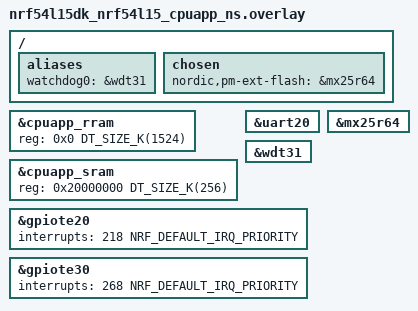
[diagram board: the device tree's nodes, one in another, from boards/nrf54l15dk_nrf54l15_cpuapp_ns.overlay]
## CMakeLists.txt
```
#
# Copyright (c) 2023 Nordic Semiconductor ASA
#
# SPDX-License-Identifier: LicenseRef-Nordic-5-Clause
#

cmake_minimum_required(VERSION 3.20.0)

find_package(Zephyr HINTS $ENV{ZEPHYR_BASE})

project(matter-template)

# Enable GNU STD support.
include(${ZEPHYR_CONNECTEDHOMEIP_MODULE_DIR}/config/nrfconnect/app/enable-gnu-std.cmake)

# NORDIC SDK APP START

# Include all source files that are located in the Matter common directory.
include(${ZEPHYR_NRF_MODULE_DIR}/samples/matter/common/cmake/source_common.cmake)

# Include Data Model utils
include(${ZEPHYR_NRF_MODULE_DIR}/samples/matter/common/cmake/data_model.cmake)

include(${ZEPHYR_NRF_MODULE_DIR}/samples/matter/common/cmake/zap_helpers.cmake)
ncs_get_zap_parent_dir(ZAP_PARENT_DIR)

target_include_directories(app PRIVATE
    src
    ${ZAP_PARENT_DIR}
)

target_sources(app PRIVATE
    src/app_task.cpp
    src/main.cpp
    src/temp_sensor_manager.cpp
    src/temperature_manager.cpp
    src/temperature_measurement/sensor.cpp
    src/zcl_callbacks.cpp
    ${ZEPHYR_NRF_MODULE_DIR}/samples/matter/common/src/binding/binding_handler.cpp
)

ncs_configure_data_model()
# NORDIC SDK APP END
```

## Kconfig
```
#
# Copyright (c) 2023 Nordic Semiconductor
#
# SPDX-License-Identifier: LicenseRef-Nordic-5-Clause
#
mainmenu "Matter Thermostat sample application"

config THERMOSTAT_TEMPERATURE_STEP
	int "Defines a simulated temperature step. Use 0 for random"
	default 0
	help
	  A temperature step that defines differences between consecutive simulated temperature measurements. If set to 0, then the step is random.

config THERMOSTAT_SIMULATED_TEMPERATURE_MAX
	int "Maximum simulated temperature value"
	default 3000

config THERMOSTAT_SIMULATED_TEMPERATURE_MIN
	int "Minimum simulated temperature value"
	default 1500

config THERMOSTAT_SIMULATED_TEMPERATURE_CHANGE
	bool "Select to set the temperature to rise or fall"
	default y
	help
	  If set to true, the simulated temperature is rising. If set to false, the simulated temperature is falling.

# Enable Read Client functionality for all build configurations.
config CHIP_ENABLE_READ_CLIENT
	default y

# Sample configuration used for Thread networking
if OPENTHREAD

choice OPENTHREAD_NORDIC_LIBRARY_CONFIGURATION
	default OPENTHREAD_NORDIC_LIBRARY_MTD
endchoice

choice OPENTHREAD_DEVICE_TYPE
	default OPENTHREAD_MTD
endchoice

endif # OPENTHREAD

source "${ZEPHYR_CONNECTEDHOMEIP_MODULE_DIR}/config/nrfconnect/chip-module/Kconfig.features"
source "${ZEPHYR_CONNECTEDHOMEIP_MODULE_DIR}/config/nrfconnect/chip-module/Kconfig.defaults"
source "${ZEPHYR_NRF_MODULE_DIR}/samples/matter/common/src/Kconfig"
source "Kconfig.zephyr"
```

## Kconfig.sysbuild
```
#
# Copyright (c) 2023 Nordic Semiconductor ASA
#
# SPDX-License-Identifier: LicenseRef-Nordic-5-Clause
#

config WIFI_NRF70
	default y if BOARD_NRF7002DK

#### Radio core selection
config NRF_DEFAULT_IPC_RADIO
	default y

# Enable IEEE802.15.4 serialization to network core
# This config automatically pulls in the `overlay-802154.conf` in the ipc_radio image
config NETCORE_IPC_RADIO_IEEE802154
	default y if SOC_SERIES_NRF53X && !WIFI_NRF70

# Enable Bluetooth serialization to network core
# This config automatically pulls in the `overlay-bt_hci_ipc.conf` in the ipc_radio image
config NETCORE_IPC_RADIO_BT_HCI_IPC
	default y if SOC_SERIES_NRF53X

#### Bootloader
choice BOOTLOADER
	default BOOTLOADER_MCUBOOT
endchoice

if BOOTLOADER_MCUBOOT

#### DFU multi-image support
config DFU_MULTI_IMAGE_PACKAGE_BUILD
	default y

config DFU_MULTI_IMAGE_PACKAGE_APP
	default y

config PM_EXTERNAL_FLASH_MCUBOOT_SECONDARY
	default y

#### DFU network core configuration
if SOC_SERIES_NRF53X

config MCUBOOT_UPDATEABLE_IMAGES
	default 2

choice MCUBOOT_MODE
	default MCUBOOT_MODE_OVERWRITE_ONLY
endchoice

choice BOOT_SIGNATURE_TYPE
	default BOOT_SIGNATURE_TYPE_RSA
endchoice

config SECURE_BOOT_NETCORE
	default y

config NETCORE_APP_UPDATE
	default y

config DFU_MULTI_IMAGE_PACKAGE_NET
	default y

endif # SOC_SERIES_NRF53X

if BOARD_NRF54L15DK

config PM_OVERRIDE_EXTERNAL_DRIVER_CHECK
	default y

endif # BOARD_NRF54L15DK

endif # BOOTLOADER_MCUBOOT

#### Enable generating factory data
config MATTER_FACTORY_DATA_GENERATE
	default y

source "share/sysbuild/Kconfig"
```

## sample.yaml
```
sample:
  description: Matter Thermostat sample
  name: Matter Thermostat
tests:
  sample.matter.thermostat.debug:
    sysbuild: true
    build_only: true
    integration_platforms:
      - nrf52840dk/nrf52840
      - nrf5340dk/nrf5340/cpuapp
      - nrf7002dk/nrf5340/cpuapp
      - nrf54l15dk/nrf54l15/cpuapp
      - nrf54l15dk/nrf54l15/cpuapp/ns
      - nrf54lm20pdk/nrf54lm20a/cpuapp
    platform_allow:
      - nrf52840dk/nrf52840
      - nrf5340dk/nrf5340/cpuapp
      - nrf7002dk/nrf5340/cpuapp
      - nrf54l15dk/nrf54l15/cpuapp
      - nrf54l15dk/nrf54l15/cpuapp/ns
      - nrf54lm20pdk/nrf54lm20a/cpuapp
    tags:
      - sysbuild
      - ci_samples_matter
  sample.matter.thermostat.release:
    sysbuild: true
    build_only: true
    extra_args:
      - FILE_SUFFIX=release
      - SB_CONFIG_BOOTLOADER_MCUBOOT=y
      - SB_CONFIG_PARTITION_MANAGER=y
    integration_platforms:
      - nrf52840dk/nrf52840
      - nrf5340dk/nrf5340/cpuapp
      - nrf7002dk/nrf5340/cpuapp
      - nrf54l15dk/nrf54l15/cpuapp
      - nrf54lm20pdk/nrf54lm20a/cpuapp
    platform_allow:
      - nrf52840dk/nrf52840
      - nrf5340dk/nrf5340/cpuapp
      - nrf7002dk/nrf5340/cpuapp
      - nrf54l15dk/nrf54l15/cpuapp
      - nrf54lm20pdk/nrf54lm20a/cpuapp
    tags:
      - sysbuild
      - ci_samples_matter
```

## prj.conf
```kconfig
#
# Copyright (c) 2023 Nordic Semiconductor ASA
#
# SPDX-License-Identifier: LicenseRef-Nordic-5-Clause
#

# This sample uses Kconfig.defaults to set options common for all
# samples. This file should contain only options specific for this sample
# or overrides of default values.

# Enable CHIP
CONFIG_CHIP=y
CONFIG_CHIP_PROJECT_CONFIG="src/chip_project_config.h"

# Configure ZAP file name
CONFIG_NCS_SAMPLE_MATTER_ZAP_FILE_PATH="${APPLICATION_CONFIG_DIR}/src/default_zap/thermostat.zap"

# 32782 == 0x800e (example thermostat product)
CONFIG_CHIP_DEVICE_PRODUCT_ID=32782
CONFIG_STD_CPP17=y

# Enable Matter pairing automatically on application start.
CONFIG_CHIP_ENABLE_PAIRING_AUTOSTART=y

# Enable Matter extended announcement and increase duration to 1 hour.
CONFIG_CHIP_BLE_EXT_ADVERTISING=y
CONFIG_CHIP_BLE_ADVERTISING_DURATION=60

# Add support for LEDs and buttons on Nordic development kits
CONFIG_DK_LIBRARY=y

# Bluetooth Low Energy configuration
CONFIG_BT_DEVICE_NAME="MatterThermo"

# Other settings
CONFIG_THREAD_NAME=y
CONFIG_MPU_STACK_GUARD=y
CONFIG_RESET_ON_FATAL_ERROR=n
CONFIG_CHIP_LIB_SHELL=y
CONFIG_NCS_SAMPLE_MATTER_TEST_SHELL=y

# Disable NFC onboarding
CONFIG_CHIP_NFC_ONBOARDING_PAYLOAD=y

# Reduce application size
CONFIG_USE_SEGGER_RTT=n

# Enable Factory Data feature
CONFIG_CHIP_FACTORY_DATA=y
CONFIG_CHIP_FACTORY_DATA_BUILD=y
```

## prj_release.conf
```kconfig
#
# Copyright (c) 2023 Nordic Semiconductor ASA
#
# SPDX-License-Identifier: LicenseRef-Nordic-5-Clause
#

# This sample uses Kconfig.defaults to set options common for all
# samples. This file should contain only options specific for this sample
# or overrides of default values.

# Enable CHIP
CONFIG_CHIP=y
CONFIG_CHIP_PROJECT_CONFIG="src/chip_project_config.h"

# Configure ZAP file name
CONFIG_NCS_SAMPLE_MATTER_ZAP_FILE_PATH="${APPLICATION_CONFIG_DIR}/src/default_zap/thermostat.zap"

# 32782 == 0x800e (example thermostat product)
CONFIG_CHIP_DEVICE_PRODUCT_ID=32782
CONFIG_STD_CPP17=y

# Enable Matter pairing automatically on application start.
CONFIG_CHIP_ENABLE_PAIRING_AUTOSTART=y

# Enable Matter extended announcement and increase duration to 1 hour.
CONFIG_CHIP_BLE_EXT_ADVERTISING=y
CONFIG_CHIP_BLE_ADVERTISING_DURATION=60

# Add support for LEDs and buttons on Nordic development kits
CONFIG_DK_LIBRARY=y

# Bluetooth Low Energy configuration
CONFIG_BT_DEVICE_NAME="MatterThermo"

# Enable system reset on fatal error
CONFIG_RESET_ON_FATAL_ERROR=y

# Disable all debug features
CONFIG_USE_SEGGER_RTT=n
CONFIG_SHELL=n
CONFIG_OPENTHREAD_SHELL=n
CONFIG_CONSOLE=n
CONFIG_UART_CONSOLE=n
CONFIG_SERIAL=n
CONFIG_LOG=n
CONFIG_LOG_MODE_MINIMAL=n
CONFIG_ASSERT_VERBOSE=n
CONFIG_ASSERT_NO_FILE_INFO=y
CONFIG_PRINTK=n
CONFIG_PRINTK_SYNC=n
CONFIG_THREAD_NAME=n

# Disable NFC onboarding
CONFIG_CHIP_NFC_ONBOARDING_PAYLOAD=n

# Enable Factory Data feature
CONFIG_CHIP_FACTORY_DATA=y
CONFIG_CHIP_FACTORY_DATA_BUILD=y

# Enable Watchdog
CONFIG_NCS_SAMPLE_MATTER_WATCHDOG=y

# Enable LTO to decrease the flash usage.
CONFIG_LTO=y
CONFIG_ISR_TABLES_LOCAL_DECLARATION=y
```

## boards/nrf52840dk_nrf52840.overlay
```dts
/* Copyright (c) 2023 Nordic Semiconductor ASA
 *
 * SPDX-License-Identifier: LicenseRef-Nordic-5-Clause
 */

 / {
	chosen {
		nordic,pm-ext-flash = &mx25r64;
	};
};

/* Disable unused peripherals to reduce power consumption */
&adc {
	status = "disabled";
};
&uart1 {
	status = "disabled";
};
&i2c0 {
	status = "disabled";
};
&pwm0 {
	status = "disabled";
};
&spi1 {
	status = "disabled";
};
&spi3 {
	status = "disabled";
};
&usbd {
	status = "disabled";
};
```

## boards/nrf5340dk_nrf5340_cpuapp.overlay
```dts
/*
 * Copyright (c) 2023 Nordic Semiconductor ASA
 *
 * SPDX-License-Identifier: LicenseRef-Nordic-5-Clause
 */

/ {
	chosen {
		nordic,pm-ext-flash = &mx25r64;
	};
};

/* Disable unused peripherals to reduce power consumption */
&adc {
	status = "disabled";
};
&i2c1 {
	status = "disabled";
};
&pwm0 {
	status = "disabled";
};
&spi2 {
	status = "disabled";
};
&usbd {
	status = "disabled";
};
```

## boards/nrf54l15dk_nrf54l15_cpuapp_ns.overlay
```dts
/*
 * Copyright (c) 2024 Nordic Semiconductor ASA
 *
 * SPDX-License-Identifier: LicenseRef-Nordic-5-Clause
 */

/ {
	aliases {
		// Use watchdog wdt31 as the application watchdog
		watchdog0 = &wdt31;
	};

	chosen {
		nordic,pm-ext-flash = &mx25r64;
	};
};

// restore full RRAM and SRAM space - by default some parts are dedicated to FLRP
&cpuapp_rram {
	reg = <0x0 DT_SIZE_K(1524)>;
};

&cpuapp_sram {
	reg = <0x20000000 DT_SIZE_K(256)>;
	ranges = <0x0 0x20000000  0x40000>;
};

// TODO: re-enable HWFC once it's fixed
&uart20 {
	/delete-property/ hw-flow-control;
};

&mx25r64 {
	status = "okay";
};

&wdt31 {
	status = "okay";
};

// Change IRQ ids to handle button interrupts.

// The default values for nRF54L15 are 219 and 269,
// but with TF-M they are reserved for the secure domain
// (218 and 268 are reserved for the non-secure domain).
&gpiote20 {
	interrupts = <218 NRF_DEFAULT_IRQ_PRIORITY>;
};

&gpiote30 {
	interrupts = <268 NRF_DEFAULT_IRQ_PRIORITY>;
};
```

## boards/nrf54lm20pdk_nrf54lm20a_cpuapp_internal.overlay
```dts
/*
 * Copyright (c) 2025 Nordic Semiconductor ASA
 *
 * SPDX-License-Identifier: LicenseRef-Nordic-5-Clause
 */

/ {
	aliases {
		// Use watchdog wdt31 as the application watchdog
		watchdog0 = &wdt31;
	};
};

// restore full RRAM and SRAM space - by default some parts are dedicated to FLRP
&cpuapp_rram {
	reg = <0x0 DT_SIZE_K(2036)>;
};

&cpuapp_sram {
	reg = <0x20000000 DT_SIZE_K(512)>;
	ranges = <0x0 0x20000000  0x80000>;
};

&mx25r64 {
	status = "disabled";
};

&wdt31 {
	status = "okay";
};
```

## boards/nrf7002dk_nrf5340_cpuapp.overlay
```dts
/*
 * Copyright (c) 2023 Nordic Semiconductor ASA
 *
 * SPDX-License-Identifier: LicenseRef-Nordic-5-Clause
 */

/ {
	chosen {
		nordic,pm-ext-flash = &mx25r64;
	};

	aliases {
		watchdog0 = &wdt0;
	};
};
```

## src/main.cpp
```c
/*
 * Copyright (c) 2023 Nordic Semiconductor ASA
 *
 * SPDX-License-Identifier: LicenseRef-Nordic-5-Clause
 */

#include "app_task.h"

#include <zephyr/logging/log.h>

LOG_MODULE_REGISTER(app, CONFIG_MATTER_LOG_LEVEL);

int main()
{
	CHIP_ERROR err = AppTask::Instance().StartApp();

	LOG_ERR("Exited with code %" CHIP_ERROR_FORMAT, err.Format());
	return err == CHIP_NO_ERROR ? EXIT_SUCCESS : EXIT_FAILURE;
}
```

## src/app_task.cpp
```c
/*
 * Copyright (c) 2023 Nordic Semiconductor ASA
 *
 * SPDX-License-Identifier: LicenseRef-Nordic-5-Clause
 */

#include "app_task.h"

#include "temp_sensor_manager.h"
#include "temperature_manager.h"

#include "app/matter_init.h"
#include "app/task_executor.h"

#include <app-common/zap-generated/attributes/Accessors.h>
#include <app/clusters/identify-server/identify-server.h>
#include <setup_payload/OnboardingCodesUtil.h>

#include <zephyr/logging/log.h>

LOG_MODULE_DECLARE(app, CONFIG_MATTER_LOG_LEVEL);

using namespace ::chip;
using namespace ::chip::app;
using namespace ::chip::DeviceLayer;

namespace
{
constexpr EndpointId kThermostatEndpointId = 1;

Identify sIdentify = { kThermostatEndpointId, AppTask::IdentifyStartHandler, AppTask::IdentifyStopHandler,
		       Clusters::Identify::IdentifyTypeEnum::kVisibleIndicator };

#define TEMPERATURE_BUTTON_MASK DK_BTN2_MSK
} // namespace

void AppTask::IdentifyStartHandler(Identify *)
{
	Nrf::PostTask(
		[] { Nrf::GetBoard().GetLED(Nrf::DeviceLeds::LED2).Blink(Nrf::LedConsts::kIdentifyBlinkRate_ms); });
}

void AppTask::IdentifyStopHandler(Identify *)
{
	Nrf::PostTask([] { Nrf::GetBoard().GetLED(Nrf::DeviceLeds::LED2).Set(false); });
}

void AppTask::ButtonEventHandler(Nrf::ButtonState state, Nrf::ButtonMask hasChanged)
{
	if (TEMPERATURE_BUTTON_MASK & hasChanged) {
		TemperatureButtonAction action = (TEMPERATURE_BUTTON_MASK & state) ? TemperatureButtonAction::Pushed :
										     TemperatureButtonAction::Released;
		Nrf::PostTask([action] { ThermostatHandler(action); });
	}
}

void AppTask::ThermostatHandler(const TemperatureButtonAction &action)
{
	if (action == TemperatureButtonAction::Pushed) {
		TemperatureManager::Instance().LogThermostatStatus();
	}
}

CHIP_ERROR AppTask::Init()
{
	/* Initialize Matter stack */
	ReturnErrorOnFailure(Nrf::Matter::PrepareServer(Nrf::Matter::InitData{ .mPostServerInitClbk = [] {
		CHIP_ERROR err = TempSensorManager::Instance().Init();
		if (err != CHIP_NO_ERROR) {
			LOG_ERR("TempSensorManager Init fail");
			return err;
		}
		err = TemperatureManager::Instance().Init();
		if (err != CHIP_NO_ERROR) {
			LOG_ERR("TemperatureManager Init fail");
		}
		return err;
	} }));

	if (!Nrf::GetBoard().Init(ButtonEventHandler)) {
		LOG_ERR("User interface initialization failed.");
		return CHIP_ERROR_INCORRECT_STATE;
	}

	/* Register Matter event handler that controls the connectivity status LED based on the captured Matter network
	 * state. */
	ReturnErrorOnFailure(Nrf::Matter::RegisterEventHandler(Nrf::Board::DefaultMatterEventHandler, 0));

	return Nrf::Matter::StartServer();
}

CHIP_ERROR AppTask::StartApp()
{
	ReturnErrorOnFailure(Init());

	while (true) {
		Nrf::DispatchNextTask();
	}

	return CHIP_NO_ERROR;
}
```

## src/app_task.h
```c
/*
 * Copyright (c) 2023 Nordic Semiconductor ASA
 *
 * SPDX-License-Identifier: LicenseRef-Nordic-5-Clause
 */

#pragma once

#include "board/board.h"

#include <platform/CHIPDeviceLayer.h>

struct Identify;

enum class TemperatureButtonAction : uint8_t { Pushed, Released };

class AppTask {
public:
	static AppTask &Instance()
	{
		static AppTask sAppTask;
		return sAppTask;
	};

	CHIP_ERROR StartApp();

	static void IdentifyStartHandler(Identify *ident);
	static void IdentifyStopHandler(Identify *ident);

private:
	CHIP_ERROR Init();

	static void ButtonEventHandler(Nrf::ButtonState state, Nrf::ButtonMask hasChanged);
	static void ThermostatHandler(const TemperatureButtonAction &action);
};
```

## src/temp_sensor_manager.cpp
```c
/*
 * Copyright (c) 2023 Nordic Semiconductor ASA
 *
 * SPDX-License-Identifier: LicenseRef-Nordic-5-Clause
 */

#include "temp_sensor_manager.h"
#include "app/task_executor.h"
#include "temperature_measurement/sensor.h"

LOG_MODULE_DECLARE(app, CONFIG_CHIP_APP_LOG_LEVEL);

using namespace chip;
using namespace chip::DeviceLayer;

static constexpr EndpointId kThermostatEndpoint = 1;

k_timer sSensorTimer;

CHIP_ERROR TempSensorManager::Init()
{
	k_timer_init(&sSensorTimer, &TempSensorManager::TimerEventHandler, nullptr);
	k_timer_start(&sSensorTimer, K_MSEC(kSensorTimerPeriodMs), K_MSEC(kSensorTimerPeriodMs));
	/* Workaround: Default null values are not correctly propagated from the zap file. Set it manually to make sure
	 * the starting value is cleared. */
	TempSensorManager::Instance().ClearLocalTemperature();
	TempSensorManager::Instance().ClearOutdoorTemperature();
	TemperatureSensor::Instance().FullMeasurement();

	return CHIP_NO_ERROR;
}

void TempSensorManager::TimerEventHandler(k_timer *timer)
{
	Nrf::PostTask([] { TempSensorManager::SensorTimerEventHandler(); });
}

/*
 *	This function is called when the timer is stopped and initiate temperature measurement.
 *	Depending ond object given to GetMeasurement() function thermostat will use true temeprature device or simulated
 *	values
 */

void TempSensorManager::SensorTimerEventHandler()
{
	TemperatureSensor::Instance().FullMeasurement();
}

void TempSensorManager::SetLocalTemperature(int16_t temperature)
{
	PlatformMgr().LockChipStack();
	app::Clusters::Thermostat::Attributes::LocalTemperature::Set(kThermostatEndpoint, temperature);
	PlatformMgr().UnlockChipStack();
}

void TempSensorManager::ClearLocalTemperature()
{
	PlatformMgr().LockChipStack();
	app::Clusters::Thermostat::Attributes::LocalTemperature::SetNull(kThermostatEndpoint);
	PlatformMgr().UnlockChipStack();
}

void TempSensorManager::SetOutdoorTemperature(int16_t temperature)
{
	PlatformMgr().LockChipStack();
	app::Clusters::Thermostat::Attributes::OutdoorTemperature::Set(kThermostatEndpoint, temperature);
	PlatformMgr().UnlockChipStack();
}

void TempSensorManager::ClearOutdoorTemperature()
{
	PlatformMgr().LockChipStack();
	app::Clusters::Thermostat::Attributes::OutdoorTemperature::SetNull(kThermostatEndpoint);
	PlatformMgr().UnlockChipStack();
}
```

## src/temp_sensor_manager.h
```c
/*
 * Copyright (c) 2023 Nordic Semiconductor ASA
 *
 * SPDX-License-Identifier: LicenseRef-Nordic-5-Clause
 */
#pragma once

#include <stdbool.h>
#include <stdint.h>

#include <app-common/zap-generated/attributes/Accessors.h>
#include <lib/core/CHIPError.h>
#include <zephyr/kernel.h>

using namespace chip;

constexpr uint16_t kSensorTimerPeriodMs = 30000; /* 30s timer period*/

class TempSensorManager {
public:
	CHIP_ERROR Init();

	static TempSensorManager &Instance()
	{
		static TempSensorManager sTempSensorManager;
		return sTempSensorManager;
	};

	static void SetLocalTemperature(int16_t temperature);
	static void ClearLocalTemperature();
	static void SetOutdoorTemperature(int16_t temperature);
	static void ClearOutdoorTemperature();

private:
	static void TimerEventHandler(k_timer *timer);
	static void SensorTimerEventHandler();
};
```

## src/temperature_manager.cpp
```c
/*
 * Copyright (c) 2023 Nordic Semiconductor ASA
 *
 * SPDX-License-Identifier: LicenseRef-Nordic-5-Clause
 */

#include "temperature_manager.h"
#include <app-common/zap-generated/cluster-objects.h>
#include <platform/PlatformManager.h>
#include <zephyr/logging/log.h>

LOG_MODULE_DECLARE(app, CONFIG_CHIP_APP_LOG_LEVEL);

using namespace chip;
using namespace ::chip::DeviceLayer;
using namespace ::chip::app::Clusters;
using namespace chip::app::Clusters::Thermostat::Attributes;
using namespace Protocols::InteractionModel;

constexpr EndpointId kThermostatEndpoint = 1;

namespace
{

/* Convert and return only complete part of value to printable type */
uint8_t ReturnCompleteValue(int16_t Value)
{
	return static_cast<uint8_t>(Value / 100);
}

/* Converts and returns only reminder part of value to printable type.
 * This formula rounds reminder value to one significant figure
 */

uint8_t ReturnRemainderValue(int16_t Value)
{
	return static_cast<uint8_t>((Value % 100 + 5) / 10);
}

} // namespace

CHIP_ERROR TemperatureManager::Init()
{
	CHIP_ERROR err = CHIP_NO_ERROR;

	PlatformMgr().LockChipStack();

	VerifyOrExit(Status::Success == LocalTemperature::Get(kThermostatEndpoint, mLocalTempCelsius),
		     err = CHIP_IM_GLOBAL_STATUS(Failure));
	VerifyOrExit(Status::Success == OutdoorTemperature::Get(kThermostatEndpoint, mOutdoorTempCelsius),
		     err = CHIP_IM_GLOBAL_STATUS(Failure));
	VerifyOrExit(Status::Success == OccupiedCoolingSetpoint::Get(kThermostatEndpoint, &mCoolingCelsiusSetPoint),
		     err = CHIP_IM_GLOBAL_STATUS(Failure));
	VerifyOrExit(Status::Success == OccupiedHeatingSetpoint::Get(kThermostatEndpoint, &mHeatingCelsiusSetPoint),
		     err = CHIP_IM_GLOBAL_STATUS(Failure));
	VerifyOrExit(Status::Success == SystemMode::Get(kThermostatEndpoint, &mThermMode),
		     err = CHIP_IM_GLOBAL_STATUS(Failure));

exit:
	PlatformMgr().UnlockChipStack();

	return err;
}

void TemperatureManager::LogThermostatStatus()
{
	LOG_INF("Thermostat:");
	LOG_INF("	Mode - %d", static_cast<uint8_t>(mThermMode));
	if (!(GetLocalTemp().IsNull())) {
		int16_t tempValue = GetLocalTemp().Value();
		LOG_INF("	LocalTemperature - %d,%d'C", ReturnCompleteValue(tempValue),
			ReturnRemainderValue(tempValue));
	} else {
		LOG_INF("	LocalTemperature - No Value");
	}
	if (!(GetOutdoorTemp().IsNull())) {
		int16_t tempValue = GetOutdoorTemp().Value();
		LOG_INF("	OutdoorTemperature - %d,%d'C", ReturnCompleteValue(tempValue),
			ReturnRemainderValue(tempValue));
	} else {
		LOG_INF("	OutdoorTemperature - No Value");
	}
	LOG_INF("	HeatingSetpoint - %d,%d'C", ReturnCompleteValue(mHeatingCelsiusSetPoint),
		ReturnRemainderValue(mHeatingCelsiusSetPoint));
	LOG_INF("	CoolingSetpoint - %d,%d'C \n", ReturnCompleteValue(mCoolingCelsiusSetPoint),
		ReturnRemainderValue(mCoolingCelsiusSetPoint));
}

void TemperatureManager::AttributeChangeHandler(EndpointId endpointId, AttributeId attributeId, uint8_t *value,
						uint16_t size)
{
	Status status;

	switch (attributeId) {
	case LocalTemperature::Id: {
		status = LocalTemperature::Get(kThermostatEndpoint, mLocalTempCelsius);
		VerifyOrReturn(Status::Success == status,
			       LOG_ERR("Failed to get Thermostat LocalTemperature attribute"));
	} break;

	case OutdoorTemperature::Id: {
		status = OutdoorTemperature::Get(kThermostatEndpoint, mOutdoorTempCelsius);
		VerifyOrReturn(Status::Success == status,
			       LOG_ERR("Failed to get Thermostat OutdoorTemperature attribute"));
	} break;

	case OccupiedCoolingSetpoint::Id: {
		mCoolingCelsiusSetPoint = *reinterpret_cast<int16_t *>(value);
		LOG_INF("Cooling TEMP: %d", mCoolingCelsiusSetPoint);
	} break;

	case OccupiedHeatingSetpoint::Id: {
		mHeatingCelsiusSetPoint = *reinterpret_cast<int16_t *>(value);
		LOG_INF("Heating TEMP %d", mHeatingCelsiusSetPoint);
	} break;

	case SystemMode::Id: {
		mThermMode = static_cast<app::Clusters::Thermostat::SystemModeEnum>(*value);
	} break;

	default: {
		LOG_ERR("Unhandled thermostat attribute %x", attributeId);
		return;
	} break;
	}

	LogThermostatStatus();
}

app::DataModel::Nullable<int16_t> TemperatureManager::GetLocalTemp()
{
	return mLocalTempCelsius;
}

app::DataModel::Nullable<int16_t> TemperatureManager::GetOutdoorTemp()
{
	return mOutdoorTempCelsius;
}
```

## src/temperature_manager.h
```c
/*
 * Copyright (c) 2023 Nordic Semiconductor ASA
 *
 * SPDX-License-Identifier: LicenseRef-Nordic-5-Clause
 */
#pragma once

#include <stdbool.h>
#include <stdint.h>

#include <app-common/zap-generated/attributes/Accessors.h>

#include <lib/core/CHIPError.h>

using namespace chip;

class TemperatureManager {
public:
	static TemperatureManager &Instance()
	{
		static TemperatureManager sTemperatureManager;
		return sTemperatureManager;
	};

	CHIP_ERROR Init();
	void AttributeChangeHandler(EndpointId endpointId, AttributeId attributeId, uint8_t *value, uint16_t size);
	app::DataModel::Nullable<int16_t> GetLocalTemp();
	app::DataModel::Nullable<int16_t> GetOutdoorTemp();

	void LogThermostatStatus();

private:
	app::DataModel::Nullable<int16_t> mLocalTempCelsius;
	app::DataModel::Nullable<int16_t> mOutdoorTempCelsius;
	int16_t mCoolingCelsiusSetPoint;
	int16_t mHeatingCelsiusSetPoint;
	app::Clusters::Thermostat::SystemModeEnum mThermMode;
};
```

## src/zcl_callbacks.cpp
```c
/*
 * Copyright (c) 2023 Nordic Semiconductor ASA
 *
 *
 * SPDX-License-Identifier: LicenseRef-Nordic-5-Clause
 */

#include "app_task.h"
#include "temp_sensor_manager.h"
#include "temperature_manager.h"

#include <app-common/zap-generated/ids/Attributes.h>
#include <app-common/zap-generated/ids/Clusters.h>
#include <app/ConcreteAttributePath.h>
#include <lib/support/logging/CHIPLogging.h>

LOG_MODULE_DECLARE(app, CONFIG_CHIP_APP_LOG_LEVEL);

using namespace chip;
using namespace chip::app::Clusters;

void MatterPostAttributeChangeCallback(const chip::app::ConcreteAttributePath &attributePath, uint8_t type,
				       uint16_t size, uint8_t *value)
{
	ClusterId clusterId = attributePath.mClusterId;
	AttributeId attributeId = attributePath.mAttributeId;
	ChipLogProgress(Zcl, "Cluster callback: " ChipLogFormatMEI, ChipLogValueMEI(clusterId));

	if (clusterId == Identify::Id) {
		ChipLogProgress(Zcl, "Identify attribute ID: " ChipLogFormatMEI " Type: %u Value: %u, length %u",
				ChipLogValueMEI(attributeId), type, *value, size);
	} else if (clusterId == Thermostat::Id) {
		TemperatureManager::Instance().AttributeChangeHandler(attributePath.mEndpointId, attributeId, value,
								      size);
	}
}
```
